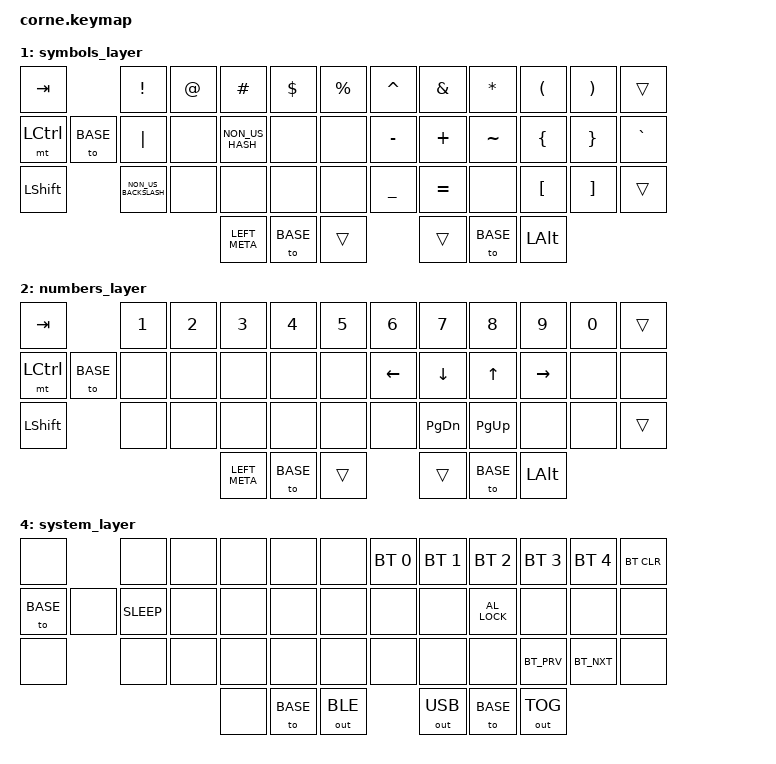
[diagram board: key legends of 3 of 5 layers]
/* vim: filetype=c
 * Copyright (c) 2020, 2023 The ZMK Contributors, Jonathan Wright
 *
 * SPDX-License-Identifier: MIT
 */

#include <behaviors.dtsi>
#include <dt-bindings/zmk/keys.h>
#include <dt-bindings/zmk/bt.h>
#include <dt-bindings/zmk/outputs.h>

// Prepare the Layers
#define BASE      0
#define SYMBOLS   1
#define NUMBERS   2
#define MEDIA     3
#define SYSTEM    4

// TAP_DANCE settings
#define TAP_SPEED 200

&sk {
    release-after-ms = <2000>;
    quick-release;
};

&mt {
  tapping-term-ms = <400>;
  retro-tap;
};

&soft_off {
    hold-time-ms = <2000>;
};

/ {

  behaviors {

    ms: mod_sticky {
      compatible = "zmk,behavior-hold-tap";
      #binding-cells = <2>;
      flavor = "hold-preferred";
      tapping-term-ms = <200>;
      bindings = <&mo>, <&sl>;
    };

    kpt: kp_toggle {
      compatible = "zmk,behavior-hold-tap";
      #binding-cells = <2>;
      flavor = "hold-preferred";
      tapping-term-ms = <200>;
      bindings = <&kp>, <&tog>;
    };
  };

  combos {
    compatible = "zmk,combos";

    // Power off the left-hand keyboard
    left_soft_off {
      timeout-ms = <100>;
      layers = <0>; // limit to the BASE layer
      key-positions = <37 38 39>;
      bindings = <&soft_off>;
    };

    // Power off the right-hand keyboard
    right_soft_off {
      timeout-ms = <100>;
      layers = <0>; // limit to the BASE layer
      key-positions = <40 41 42>;
      bindings = <&soft_off>;
    };
  };

  keymap {
    compatible = "zmk,keymap";

    // ╭────┬────┬────┬────┬────┬────╮ ╭────┬────┬────┬────┬────┬────╮
    // │ 01 │ 02 │ 03 │ 04 │ 05 │ 06 │ │ 07 │ 08 │ 09 │ 10 │ 11 │ 12 │
    // ├────┼────┼────┼────┼────┼────┤ ├────┼────┼────┼────┼────┼────┤
    // │ 13 │ 14 │ 15 │ 16 │ 17 │ 18 │ │ 19 │ 20 │ 21 │ 22 │ 23 │ 24 │
    // ├────┼────┼────┼────┼────┼────┤ ├────┼────┼────┼────┼────┼────┤
    // │ 25 │ 26 │ 27 │ 28 │ 29 │ 30 │ │ 31 │ 32 │ 33 │ 34 │ 35 │ 36 │
    // ╰────┴────┴────┼────┼────┼────┤ ├────┼────┼────┼────┴────┴────╯
    //                │ 37 │ 38 │ 39 │ │ 40 │ 41 │ 42 │
    //                ╰────┴────┴────╯ ╰────┴────┴────╯

    default_layer {
      bindings = <
        // ╭─────────────────────────┬───────┬───────┬───────┬───────┬───────╮ ╭───────┬───────┬───────────┬────────────┬───────────────┬──────────────────╮
             &lt MEDIA TAB             &kp Q   &kp W   &kp E   &kp R   &kp T     &kp Y   &kp U   &kp I       &kp O        &kp P           &kp BACKSPACE
        // ├─────────────────────────┼───────┼───────┼───────┼───────┼───────┤ ├───────┼───────┼───────────┼────────────┼───────────────┼──────────────────┤
             &mt LEFT_CONTROL ESCAPE   &kp A   &kp S   &kp D   &kp F   &kp G     &kp H   &kp J   &kp K       &kp L        &kp SEMICOLON   &kp SINGLE_QUOTE
        // ├─────────────────────────┼───────┼───────┼───────┼───────┼───────┤ ├───────┼───────┼───────────┼────────────┼───────────────┼──────────────────┤
             &mt LEFT_SHIFT CAPSLOCK   &kp Z   &kp X   &kp C   &kp V   &kp B     &kp N   &kp M   &kp COMMA   &kp PERIOD   &kp SLASH       &kp RIGHT_SHIFT
        // ╰───────┬─────────────────┴─────┬──┴───────┴──────┴───┬───┴───────┤ ├───────┴───┬───┴───────────┴─────┬──────┴──────────────┬┴──────────────────╯
                     &kpt LEFT_META SYSTEM   &ms NUMBERS NUMBERS   &kp SPACE     &kp ENTER   &ms SYMBOLS SYMBOLS   &kpt LEFT_ALT MEDIA
        //         ╰───────────────────────┴─────────────────────┴───────────╯ ╰───────────┴─────────────────────┴─────────────────────╯
      >;
    };

    symbols_layer { // right modifier
      bindings = <
        // ╭───────────────────────────┬──────────────────────┬─────────────┬─────────────────┬────────────┬─────────────╮ ╭────────────────┬───────────────┬──────────────┬──────────────────────┬───────────────────────┬───────────╮
             &kp TAB                     &kp EXCLAMATION        &kp AT_SIGN   &kp HASH          &kp DOLLAR   &kp PERCENT     &kp CARET        &kp AMPERSAND   &kp ASTERISK   &kp LEFT_PARENTHESIS   &kp RIGHT_PARENTHESIS   &trans
        // ├───────────────────────────┼──────────────────────┼─────────────┼─────────────────┼────────────┼─────────────┤ ├────────────────┼───────────────┼──────────────┼──────────────────────┼───────────────────────┼───────────┤
             &mt LEFT_CONTROL &to BASE   &kp PIPE               &none         &kp NON_US_HASH   &none        &none           &kp MINUS        &kp PLUS        &kp TILDE      &kp LEFT_BRACE         &kp RIGHT_BRACE         &kp GRAVE
        // ├───────────────────────────┼──────────────────────┼─────────────┼─────────────────┼────────────┼─────────────┤ ├────────────────┼───────────────┼──────────────┼──────────────────────┼───────────────────────┼───────────┤
             &kp LEFT_SHIFT              &kp NON_US_BACKSLASH   &none         &none             &none        &none           &kp UNDERSCORE   &kp EQUAL       &none          &kp LEFT_BRACKET       &kp RIGHT_BRACKET       &trans
        // ╰───────────────────────────┴──────────────────────┴─────────────┴────────┬────────┴──────┬─────┴────┬────────┤ ├────────┬───────┴──┬────────────┴─┬────────────┴──────────────────────┴───────────────────────┴───────────╯
                                                                                       &kp LEFT_META   &to BASE   &trans     &trans   &to BASE   &kp LEFT_ALT
        //                                                                           ╰───────────────┴──────────┴────────╯ ╰────────┴──────────┴──────────────╯
      >;
    };

    numbers_layer {
      bindings = <
        // ╭───────────────────────────┬────────┬────────┬────────┬────────┬────────╮ ╭──────────┬───────────────┬─────────────┬───────────┬────────┬────────╮
             &kp TAB                     &kp N1   &kp N2   &kp N3   &kp N4   &kp N5     &kp N6     &kp N7          &kp N8        &kp N9      &kp N0   &trans
        // ├───────────────────────────┼────────┼────────┼────────┼────────┼────────┤ ├──────────┼───────────────┼─────────────┼───────────┼────────┼────────┤
             &mt LEFT_CONTROL &to BASE   &none    &none    &none    &none    &none      &kp LEFT   &kp DOWN        &kp UP        &kp RIGHT   &none    &none
        // ├───────────────────────────┼────────┼────────┼────────┼────────┼────────┤ ├──────────┼───────────────┼─────────────┼───────────┼────────┼────────┤
             &kp LEFT_SHIFT              &none    &none    &none    &none    &none      &none      &kp PAGE_DOWN   &kp PAGE_UP   &none       &none    &trans
        // ╰───────────────────────────┴────────┼────────┴──────┬─┴────────┼────────┤ ├────────┬──┴───────┬──────┴───────┬─────┴───────────┴────────┴────────╯
                                                  &kp LEFT_META   &to BASE   &trans     &trans   &to BASE   &kp LEFT_ALT
        //                                      ╰───────────────┴──────────┴────────╯ ╰────────┴──────────┴──────────────╯

      >;
    };

    media_layer {
      bindings = <
        // ╭────────────────┬───────┬─────────────────┬───────┬───────┬───────────────────────╮ ╭──────────────┬────────────────┬────────────┬───────────────┬──────────────────┬───────────────────╮
             &none            &none   &none             &none   &none   &kp C_BRIGHTNESS_INC      &none          &none            &none        &kp C_STOP      &kp C_PLAY_PAUSE   &kp C_VOLUME_UP
        // ├────────────────┼───────┼─────────────────┼───────┼───────┼───────────────────────┤ ├──────────────┼────────────────┼────────────┼───────────────┼──────────────────┼───────────────────┤
             &to BASE         &none   &kp PRINTSCREEN   &none   &none   &kp C_BRIGHTNESS_DEC      &none          &none            &none        &none           &none              &kp C_VOLUME_DOWN
        // ├────────────────┼───────┼─────────────────┼───────┼───────┼───────────────────────┤ ├──────────────┼────────────────┼────────────┼───────────────┼──────────────────┼───────────────────┤
             &kp LEFT_SHIFT   &none   &none             &none   &none   &kp C_BRIGHTNESS_AUTO     &kp C_REPEAT   &kp C_PREVIOUS   &kp C_NEXT   &kp C_SHUFFLE   &kp C_MUTE         &trans
        // ├────────────────┴───────┴─────────────────┴───┬───┴───────┴───┬──────────┬────────┤ ├────────┬─────┴────┬───────────┴──┬─────────┴───────────────┴──────────────────┴───────────────────╯
                                                            &kp LEFT_META   &to BASE   &trans     &trans   &to BASE   &kp LEFT_ALT
        //                                                ╰───────────────┴──────────┴────────╯ ╰────────┴──────────┴──────────────╯
      >;
    };

    system_layer {
      bindings = <
        // ╭──────────┬───────┬─────────────┬───────┬───────┬───────┬───────╮ ╭──────────────┬──────────────┬───────────────┬──────────────┬──────────────┬────────────╮
             &none      &none                 &none   &none   &none   &none     &bt BT_SEL 0   &bt BT_SEL 1   &bt BT_SEL 2    &bt BT_SEL 3   &bt BT_SEL 4   &bt BT_CLR
        // ├──────────┼───────┼─────────────┼───────┼───────┼───────┼───────┤ ├──────────────┼──────────────┼───────────────┼──────────────┼──────────────┼────────────┤
             &to BASE   &none   &kp C_SLEEP   &none   &none   &none   &none     &none          &none          &kp C_AL_LOCK   &none          &none          &none
        // ├──────────┼───────┼─────────────┼───────┼───────┼───────┼───────┤ ├──────────────┼──────────────┼───────────────┼──────────────┼──────────────┼────────────┤
             &none      &none                 &none   &none   &none   &none     &none          &none          &none           &kp BT_PRV     &kp BT_NXT     &none
        // ╰──────────┴───────┴───────────┬─┴─────┬─┴───────┴┬──────┴───────┤ ├──────────────┼──────────┬───┴──────────┬────┴──────────────┴──────────────┴────────────╯
                                            &none   &to BASE   &out OUT_BLE     &out OUT_USB   &to BASE   &out OUT_TOG
        //                                ╰───────┴──────────┴──────────────╯ ╰──────────────┴──────────┴──────────────╯
      >;
    };
  };
};
